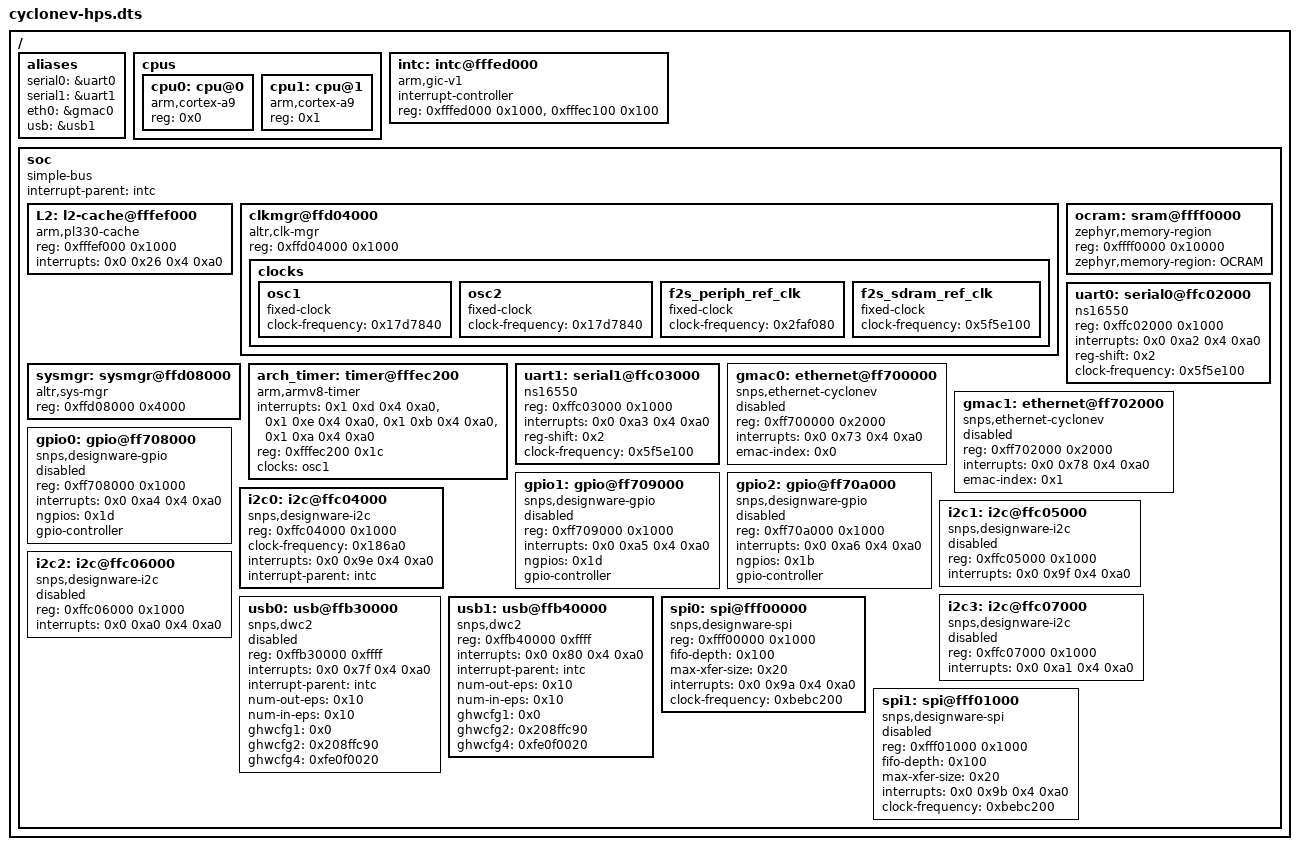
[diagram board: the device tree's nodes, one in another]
/dts-v1/;

/memreserve/ 0x0000000000000000 0x0000000000001000;

/ {
	#address-cells = < 0x1 >;
	#size-cells = < 0x1 >;
	aliases {
		serial0 = &uart0;
		serial1 = &uart1;
		eth0 = &gmac0;
		usb = &usb1;
	};
	cpus {
		#address-cells = < 0x1 >;
		#size-cells = < 0x0 >;
		cpu0: cpu@0 {
			compatible = "arm,cortex-a9";
			device_type = "cpu";
			reg = < 0x0 >;
		};
		cpu1: cpu@1 {
			compatible = "arm,cortex-a9";
			device_type = "cpu";
			reg = < 0x1 >;
		};
	};
	intc: intc@fffed000 {
		compatible = "arm,gic-v1", "arm,gic";
		#interrupt-cells = < 0x4 >;
		interrupt-controller;
		reg = < 0xfffed000 0x1000 >, < 0xfffec100 0x100 >;
		phandle = < 0x1 >;
	};
	soc {
		#address-cells = < 0x1 >;
		#size-cells = < 0x1 >;
		compatible = "simple-bus";
		device_type = "soc";
		interrupt-parent = < &intc >;
		ranges;
		L2: l2-cache@fffef000 {
			compatible = "arm,pl330-cache";
			reg = < 0xfffef000 0x1000 >;
			interrupts = < 0x0 0x26 0x4 0xa0 >;
			status = "okay";
		};
		clkmgr@ffd04000 {
			compatible = "altr,clk-mgr";
			reg = < 0xffd04000 0x1000 >;
			clocks {
				osc1: osc1 {
					#clock-cells = < 0x0 >;
					compatible = "fixed-clock";
					clock-frequency = < 0x17d7840 >;
					phandle = < 0x2 >;
				};
				osc2: osc2 {
					#clock-cells = < 0x0 >;
					compatible = "fixed-clock";
					clock-frequency = < 0x17d7840 >;
				};
				f2s_periph_ref_clk: f2s_periph_ref_clk {
					#clock-cells = < 0x0 >;
					compatible = "fixed-clock";
					clock-frequency = < 0x2faf080 >;
				};
				f2s_sdram_ref_clk: f2s_sdram_ref_clk {
					#clock-cells = < 0x0 >;
					compatible = "fixed-clock";
					clock-frequency = < 0x5f5e100 >;
				};
			};
		};
		sysmgr: sysmgr@ffd08000 {
			compatible = "altr,sys-mgr", "syscon";
			reg = < 0xffd08000 0x4000 >;
			status = "okay";
		};
		ocram: sram@ffff0000 {
			compatible = "zephyr,memory-region", "mmio-sram";
			reg = < 0xffff0000 0x10000 >;
			zephyr,memory-region = "OCRAM";
		};
		arch_timer: timer@fffec200 {
			compatible = "arm,armv8-timer";
			status = "okay";
			interrupt-names = "irq_0", "irq_1", "irq_2", "irq_3";
			interrupts = < 0x1 0xd 0x4 0xa0 >, < 0x1 0xe 0x4 0xa0 >, < 0x1 0xb 0x4 0xa0 >, < 0x1 0xa 0x4 0xa0 >;
			reg = < 0xfffec200 0x1c >;
			clocks = < &osc1 >;
		};
		uart0: serial0@ffc02000 {
			compatible = "ns16550", "snps,dw-apb-uart";
			reg = < 0xffc02000 0x1000 >;
			interrupts = < 0x0 0xa2 0x4 0xa0 >;
			reg-shift = < 0x2 >;
			clock-frequency = < 0x5f5e100 >;
			dma-names = "tx", "rx";
		};
		uart1: serial1@ffc03000 {
			compatible = "ns16550", "snps,dw-apb-uart";
			reg = < 0xffc03000 0x1000 >;
			interrupts = < 0x0 0xa3 0x4 0xa0 >;
			reg-shift = < 0x2 >;
			clock-frequency = < 0x5f5e100 >;
			dma-names = "tx", "rx";
		};
		gmac0: ethernet@ff700000 {
			compatible = "snps,ethernet-cyclonev";
			reg = < 0xff700000 0x2000 >;
			interrupts = < 0x0 0x73 0x4 0xa0 >;
			emac-index = < 0x0 >;
			status = "disabled";
		};
		gmac1: ethernet@ff702000 {
			compatible = "snps,ethernet-cyclonev";
			reg = < 0xff702000 0x2000 >;
			interrupts = < 0x0 0x78 0x4 0xa0 >;
			emac-index = < 0x1 >;
			status = "disabled";
		};
		gpio0: gpio@ff708000 {
			#address-cells = < 0x1 >;
			#size-cells = < 0x0 >;
			compatible = "snps,designware-gpio";
			reg = < 0xff708000 0x1000 >;
			interrupts = < 0x0 0xa4 0x4 0xa0 >;
			status = "disabled";
			ngpios = < 0x1d >;
			gpio-controller;
			#gpio-cells = < 0x2 >;
		};
		gpio1: gpio@ff709000 {
			#address-cells = < 0x1 >;
			#size-cells = < 0x0 >;
			compatible = "snps,designware-gpio";
			reg = < 0xff709000 0x1000 >;
			interrupts = < 0x0 0xa5 0x4 0xa0 >;
			status = "disabled";
			ngpios = < 0x1d >;
			gpio-controller;
			#gpio-cells = < 0x2 >;
		};
		gpio2: gpio@ff70a000 {
			#address-cells = < 0x1 >;
			#size-cells = < 0x0 >;
			compatible = "snps,designware-gpio";
			reg = < 0xff70a000 0x1000 >;
			interrupts = < 0x0 0xa6 0x4 0xa0 >;
			status = "disabled";
			ngpios = < 0x1b >;
			gpio-controller;
			#gpio-cells = < 0x2 >;
		};
		i2c0: i2c@ffc04000 {
			#address-cells = < 0x1 >;
			#size-cells = < 0x0 >;
			compatible = "snps,designware-i2c";
			reg = < 0xffc04000 0x1000 >;
			clock-frequency = < 0x186a0 >;
			interrupts = < 0x0 0x9e 0x4 0xa0 >;
			interrupt-parent = < &intc >;
			status = "okay";
		};
		i2c1: i2c@ffc05000 {
			#address-cells = < 0x1 >;
			#size-cells = < 0x0 >;
			compatible = "snps,designware-i2c";
			reg = < 0xffc05000 0x1000 >;
			interrupts = < 0x0 0x9f 0x4 0xa0 >;
			status = "disabled";
		};
		i2c2: i2c@ffc06000 {
			#address-cells = < 0x1 >;
			#size-cells = < 0x0 >;
			compatible = "snps,designware-i2c";
			reg = < 0xffc06000 0x1000 >;
			interrupts = < 0x0 0xa0 0x4 0xa0 >;
			status = "disabled";
		};
		i2c3: i2c@ffc07000 {
			#address-cells = < 0x1 >;
			#size-cells = < 0x0 >;
			compatible = "snps,designware-i2c";
			reg = < 0xffc07000 0x1000 >;
			interrupts = < 0x0 0xa1 0x4 0xa0 >;
			status = "disabled";
		};
		usb0: usb@ffb30000 {
			compatible = "snps,dwc2";
			reg = < 0xffb30000 0xffff >;
			interrupts = < 0x0 0x7f 0x4 0xa0 >;
			interrupt-parent = < &intc >;
			num-out-eps = < 0x10 >;
			num-in-eps = < 0x10 >;
			ghwcfg1 = < 0x0 >;
			ghwcfg2 = < 0x208ffc90 >;
			ghwcfg4 = < 0xfe0f0020 >;
			status = "disabled";
		};
		usb1: usb@ffb40000 {
			compatible = "snps,dwc2";
			reg = < 0xffb40000 0xffff >;
			interrupts = < 0x0 0x80 0x4 0xa0 >;
			interrupt-parent = < &intc >;
			num-out-eps = < 0x10 >;
			num-in-eps = < 0x10 >;
			ghwcfg1 = < 0x0 >;
			ghwcfg2 = < 0x208ffc90 >;
			ghwcfg4 = < 0xfe0f0020 >;
			status = "okay";
		};
		spi0: spi@fff00000 {
			compatible = "snps,designware-spi";
			#address-cells = < 0x1 >;
			#size-cells = < 0x0 >;
			reg = < 0xfff00000 0x1000 >;
			fifo-depth = < 0x100 >;
			max-xfer-size = < 0x20 >;
			interrupts = < 0x0 0x9a 0x4 0xa0 >;
			clock-frequency = < 0xbebc200 >;
			status = "okay";
		};
		spi1: spi@fff01000 {
			compatible = "snps,designware-spi";
			#address-cells = < 0x1 >;
			#size-cells = < 0x0 >;
			reg = < 0xfff01000 0x1000 >;
			fifo-depth = < 0x100 >;
			max-xfer-size = < 0x20 >;
			interrupts = < 0x0 0x9b 0x4 0xa0 >;
			clock-frequency = < 0xbebc200 >;
			status = "disabled";
		};
	};
};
